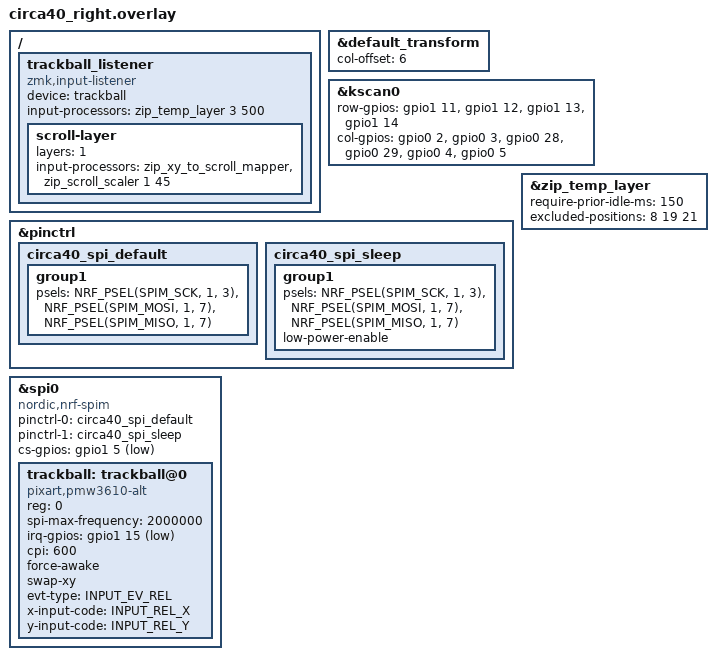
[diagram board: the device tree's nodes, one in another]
#include "circa40.dtsi"
#include <zephyr/dt-bindings/input/input-event-codes.h>
#include <dt-bindings/zmk/input_transform.h>
#include <input/processors.dtsi>
#include <zephyr/dt-bindings/pinctrl/nrf-pinctrl.h>

&default_transform { col-offset = <6>; };

&kscan0 {
    row-gpios = <&gpio1 11 (GPIO_ACTIVE_HIGH | GPIO_PULL_DOWN)>,
                <&gpio1 12 (GPIO_ACTIVE_HIGH | GPIO_PULL_DOWN)>,
                <&gpio1 13 (GPIO_ACTIVE_HIGH | GPIO_PULL_DOWN)>,
                <&gpio1 14 (GPIO_ACTIVE_HIGH | GPIO_PULL_DOWN)>;
    col-gpios = <&gpio0 2 GPIO_ACTIVE_HIGH>,
                <&gpio0 3 GPIO_ACTIVE_HIGH>,
                <&gpio0 28 GPIO_ACTIVE_HIGH>,
                <&gpio0 29 GPIO_ACTIVE_HIGH>,
                <&gpio0 4 GPIO_ACTIVE_HIGH>,
                <&gpio0 5 GPIO_ACTIVE_HIGH>;
};

&pinctrl {
    circa40_spi_default: circa40_spi_default {
        group1 {
            psels = <NRF_PSEL(SPIM_SCK, 1, 3)>,
                    <NRF_PSEL(SPIM_MOSI, 1, 7)>,
                    <NRF_PSEL(SPIM_MISO, 1, 7)>;
        };
    };
    circa40_spi_sleep: circa40_spi_sleep {
        group1 {
            psels = <NRF_PSEL(SPIM_SCK, 1, 3)>,
                    <NRF_PSEL(SPIM_MOSI, 1, 7)>,
                    <NRF_PSEL(SPIM_MISO, 1, 7)>;
            low-power-enable;
        };
    };
};

&spi0 {
    status = "okay";
    compatible = "nordic,nrf-spim";
    pinctrl-0 = <&circa40_spi_default>;
    pinctrl-1 = <&circa40_spi_sleep>;
    pinctrl-names = "default", "sleep";
    cs-gpios = <&gpio1 5 GPIO_ACTIVE_LOW>;
    trackball: trackball@0 {
        compatible = "pixart,pmw3610-alt";
        reg = <0>;
        spi-max-frequency = <2000000>;
        irq-gpios = <&gpio1 15 (GPIO_ACTIVE_LOW | GPIO_PULL_UP)>;
        cpi = <600>;
        force-awake;
        /* 実機確認: ボール上→カーソル左、ボール右→カーソル下 だったため
         * X/Y の入れ替えのみで 4 方向とも正しい向きになる（反転は不要）。 */
        swap-xy;
        evt-type = <INPUT_EV_REL>;
        x-input-code = <INPUT_REL_X>;
        y-input-code = <INPUT_REL_Y>;
    };
};

/* デフォルトの zip_temp_layer ノードを拡張:
 * - require-prior-idle-ms: 直前のキー入力から 150ms 以上経っていないと
 *   AML を発動させない（タイプ中に手のひらがボールへ軽く触れた程度の誤発動を防ぐ）。
 * - excluded-positions: FUNCTION レイヤー (circa40.keymap の3番目 = レイヤー3) の
 *   mkp MB3(8) / MB1(19) / MB2(21) の位置。この3キー以外が押されたらタイムアウト前でも
 *   即座にAML終了、この3キー（クリック自身）を押してもAMLは維持される。
 *   位置番号は circa40.dtsi の matrix-transform 順（0始まり、行ごとに連番）。 */
&zip_temp_layer {
    require-prior-idle-ms = <150>;
    excluded-positions = <8 19 21>;
};

/ {
    trackball_listener: trackball_listener {
        compatible = "zmk,input-listener";
        device = <&trackball>;

        /* Auto Mouse Layer: ボールが動いた瞬間に FUNCTION レイヤー(3, MB1/2/3)を
         * 自動オンにし、動きが無くなってから 500ms 後に自動オフに戻す。
         * 手動ホールド (&lt 3 LANGUAGE_1) との併用可。タイミングが合わなければ
         * 500 の数値だけ調整する（大きいほど戻るまで長く留まる）。 */
        input-processors = <&zip_temp_layer 3 500>;

        /* NUM レイヤー (circa40.keymap の numbers = レイヤー 1) の間だけ、
         * カーソル移動をホイールスクロールに変換する。
         * zip_xy_to_scroll_mapper: REL_Y -> WHEEL, REL_X -> HWHEEL
         * zip_scroll_scaler <倍率> <除数>: 1/45 に減速（端数は繰り越される）。
         *   速すぎ/遅すぎる場合は除数だけ変更する（大きいほど遅い）。
         * スクロール方向が逆に感じる場合は、mapper の前に
         *   <&zip_xy_transform (INPUT_TRANSFORM_Y_INVERT)>,
         * を追加する（X も反転するなら INPUT_TRANSFORM_X_INVERT を OR する）。 */
        scroll-layer {
            layers = <1>;
            input-processors = <&zip_xy_to_scroll_mapper>,
                               <&zip_scroll_scaler 1 45>;
        };
    };
};

